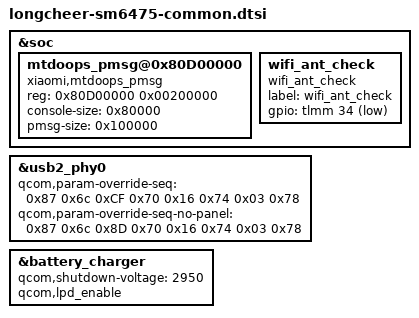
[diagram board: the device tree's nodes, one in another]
/* longcheer-sm6475-common.dtsi */
&soc {
    mtdoops_pmsg@0x80D00000 {
        compatible = "xiaomi,mtdoops_pmsg";
        reg = <0x80D00000 0x00200000>;
        console-size = <0x80000>;
        pmsg-size = <0x100000>;
    };
};

&usb2_phy0 {
	qcom,param-override-seq = <
			0x87 0x6c
			0xCF 0x70
			0x16 0x74
			0x03 0x78>;
	qcom,param-override-seq-no-panel = <
			0x87 0x6c
			0x8D 0x70
			0x16 0x74
			0x03 0x78>;
};

&battery_charger {
        qcom,shutdown-voltage = <2950>;
	qcom,lpd_enable;
};
/*lct.dongxiaolong modify for LCFEAT-128569 begin*/
&soc {
    wifi_ant_check {
        compatible = "wifi_ant_check";
        label      = "wifi_ant_check";
        gpio       = <&tlmm 34 GPIO_ACTIVE_LOW>;
        status     = "ok";
    };
};
/*lct.dongxiaolong modify for LCFEAT-128569 end*/

